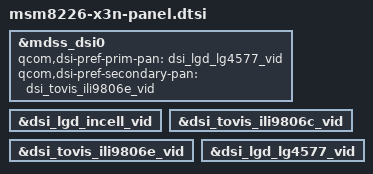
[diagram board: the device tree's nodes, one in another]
/* Copyright (c) 2013, Code Aurora Forum. All rights reserved.
 *
 * This program is free software; you can redistribute it and/or modify
 * it under the terms of the GNU General Public License version 2 and
 * only version 2 as published by the Free Software Foundation.
 *
 * This program is distributed in the hope that it will be useful,
 * but WITHOUT ANY WARRANTY; without even the implied warranty of
 * MERCHANTABILITY or FITNESS FOR A PARTICULAR PURPOSE.  See the
 * GNU General Public License for more details.
 */

&mdss_dsi0{
	qcom,dsi-pref-prim-pan = <&dsi_lgd_lg4577_vid>;
	qcom,dsi-pref-secondary-pan  =  <&dsi_tovis_ili9806e_vid>;
};

&dsi_lgd_incell_vid {
};
&dsi_tovis_ili9806c_vid{
};
&dsi_tovis_ili9806e_vid{
};
&dsi_lgd_lg4577_vid{
};
